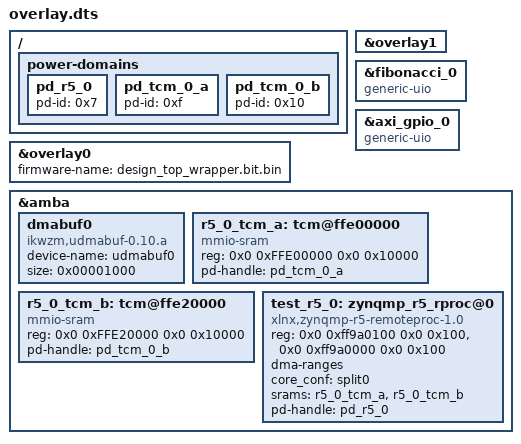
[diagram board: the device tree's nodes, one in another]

/dts-v1/;
/plugin/;
/include/ "ultra96hw.sdk/devicetree/pl.dtsi"

&overlay0 {
	firmware-name = "design_top_wrapper.bit.bin";
};
&overlay1 {
	#address-cells = <2>;
	#size-cells = <2>;
};

&fibonacci_0 {
	compatible = "generic-uio";
};
&axi_gpio_0 {
	compatible = "generic-uio";
};

/ {
	fragment@2 {
		target = <&amba>;
		overlay2: __overlay__ {
			dmabuf0 {
				compatible  = "ikwzm,udmabuf-0.10.a";
				device-name = "udmabuf0";
				size = <0x00001000>;
			};
		};
	};
	fragment@3 {
		target-path = "/";
		overlay3: __overlay__ {
			power-domains {
				pd_r5_0: pd_r5_0 {
					#power-domain-cells = <0x0>;
					pd-id = <0x7>;
				};
				pd_tcm_0_a: pd_tcm_0_a {
					#power-domain-cells = <0x0>;
					pd-id = <0xf>;
				};
				pd_tcm_0_b: pd_tcm_0_b {
					#power-domain-cells = <0x0>;
					pd-id = <0x10>;
				};
			};
		};
	};
	fragment@4 {
		target = <&amba>;
		overlay4: __overlay__ {
			#address-cells = <2>;
			#size-cells = <2>;
			/* firmware memory nodes */
			r5_0_tcm_a: tcm@ffe00000 {
				compatible = "mmio-sram";
				reg = <0x0 0xFFE00000 0x0 0x10000>;
				pd-handle = <&pd_tcm_0_a>;
			};
			r5_0_tcm_b: tcm@ffe20000 {
				compatible = "mmio-sram";
				reg = <0x0 0xFFE20000 0x0 0x10000>;
				pd-handle = <&pd_tcm_0_b>;
			};
			test_r5_0: zynqmp_r5_rproc@0 {
				compatible = "xlnx,zynqmp-r5-remoteproc-1.0";
				reg = <0x0 0xff9a0100 0x0 0x100>, <0x0 0xff9a0000 0x0 0x100>;
				reg-names = "rpu_base", "rpu_glbl_base";
				dma-ranges;
				core_conf = "split0";
				srams = <&r5_0_tcm_a &r5_0_tcm_b>;
				pd-handle = <&pd_r5_0>;
			};
		};
	};
};

